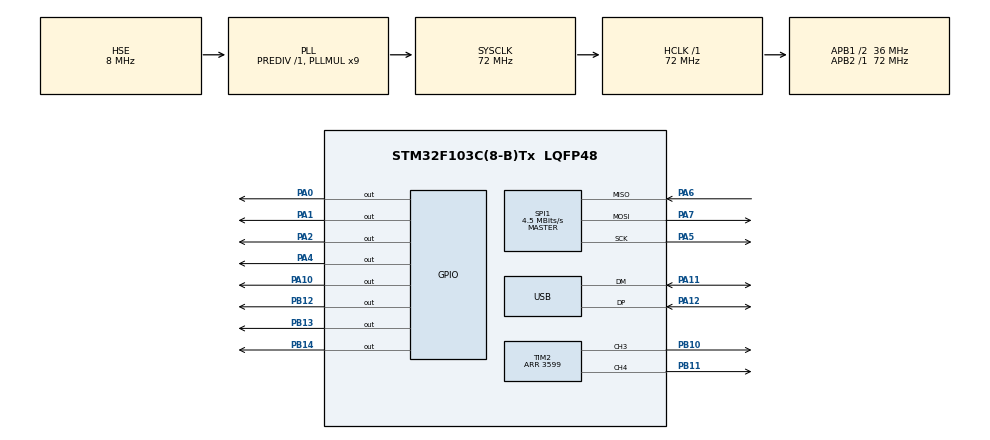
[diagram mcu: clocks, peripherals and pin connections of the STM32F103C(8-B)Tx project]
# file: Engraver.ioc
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Mcu.Family=STM32F1
Mcu.Name=STM32F103C(8-B)Tx
Mcu.Package=LQFP48
NVIC.PriorityGroup=NVIC_PRIORITYGROUP_4
NVIC.TIM4_IRQn=true\:0\:0\:false\:false\:true
NVIC.USB_LP_CAN1_RX0_IRQn=true\:0\:0\:false\:false\:true
PA0-WKUP.GPIO_Speed=GPIO_SPEED_FREQ_HIGH
PA0-WKUP.Signal=GPIO_Output
PA1.GPIO_Speed=GPIO_SPEED_FREQ_HIGH
PA1.Signal=GPIO_Output
PA10.GPIO_Speed=GPIO_SPEED_FREQ_HIGH
PA10.PinState=GPIO_PIN_SET
PA10.Signal=GPIO_Output
PA11.Mode=Device
PA11.Signal=USB_DM
PA12.Mode=Device
PA12.Signal=USB_DP
PA13.Mode=Serial_Wire
PA13.Signal=SYS_JTMS-SWDIO
PA14.Mode=Serial_Wire
PA14.Signal=SYS_JTCK-SWCLK
PA2.GPIO_Speed=GPIO_SPEED_FREQ_HIGH
PA2.Signal=GPIO_Output
PA4.GPIO_Speed=GPIO_SPEED_FREQ_HIGH
PA4.Signal=GPIO_Output
PA5.Mode=Full_Duplex_Master
PA5.Signal=SPI1_SCK
PA6.Mode=Full_Duplex_Master
PA6.Signal=SPI1_MISO
PA7.Mode=Full_Duplex_Master
PA7.Signal=SPI1_MOSI
PB10.GPIO_Speed=GPIO_SPEED_FREQ_HIGH
PB10.Signal=S_TIM2_CH3
PB11.GPIO_Speed=GPIO_SPEED_FREQ_HIGH
PB11.Signal=S_TIM2_CH4
PB12.GPIO_Speed=GPIO_SPEED_FREQ_HIGH
PB12.Signal=GPIO_Output
PB13.GPIO_Speed=GPIO_SPEED_FREQ_HIGH
PB13.Signal=GPIO_Output
PB14.GPIO_Speed=GPIO_SPEED_FREQ_HIGH
PB14.Signal=GPIO_Output
PD0-OSC_IN.Mode=HSE-External-Oscillator
PD0-OSC_IN.Signal=RCC_OSC_IN
PD1-OSC_OUT.Mode=HSE-External-Oscillator
PD1-OSC_OUT.Signal=RCC_OSC_OUT
ProjectManager.HeapSize=0x200
ProjectManager.StackSize=0x400
ProjectManager.TargetToolchain=SW4STM32
RCC.AHBFreq_Value=72000000
RCC.APB1CLKDivider=RCC_HCLK_DIV2
RCC.APB1Freq_Value=36000000
RCC.APB1TimFreq_Value=72000000
RCC.APB2Freq_Value=72000000
RCC.APB2TimFreq_Value=72000000
RCC.HCLKFreq_Value=72000000
RCC.HSIState=RCC_HSI_ON
RCC.PLLMUL=RCC_PLL_MUL9
RCC.SYSCLKFreq_VALUE=72000000
RCC.SYSCLKSource=RCC_SYSCLKSOURCE_PLLCLK
RCC.USBFreq_Value=48000000
RCC.USBPrescaler=RCC_USBCLKSOURCE_PLL_DIV1_5
SH.S_TIM2_CH3.0=TIM2_CH3,PWM Generation3 CH3
SH.S_TIM2_CH4.0=TIM2_CH4,PWM Generation4 CH4
SPI1.BaudRatePrescaler=SPI_BAUDRATEPRESCALER_16
SPI1.CalculateBaudRate=4.5 MBits/s
SPI1.Mode=SPI_MODE_MASTER
TIM2.Channel-PWM\ Generation3\ CH3=TIM_CHANNEL_3
TIM2.Channel-PWM\ Generation4\ CH4=TIM_CHANNEL_4
TIM2.OCFastMode_PWM-PWM\ Generation3\ CH3=TIM_OCFAST_ENABLE
TIM2.OCFastMode_PWM-PWM\ Generation4\ CH4=TIM_OCFAST_ENABLE
TIM2.Period=3599
TIM3.Period=71
TIM4.Period=65535
TIM4.Prescaler=99
USB_DEVICE.CLASS_NAME_FS=CDC
USB_DEVICE.USBD_HandleTypeDef=hUsbDeviceFS
USB_DEVICE.VirtualMode=Cdc
USB_DEVICE.VirtualModeFS=Cdc_FS
VP_CRC_VS_CRC.Mode=CRC_Activate
VP_TIM3_VS_ClockSourceINT.Mode=Internal
VP_TIM4_VS_ClockSourceINT.Mode=Internal
VP_USB_DEVICE_VS_USB_DEVICE_CDC_FS.Mode=CDC_FS
board=Engraver

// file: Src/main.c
/**
  ******************************************************************************
  * File Name          : main.c
  * Description        : Main program body
  ******************************************************************************
  *
  * COPYRIGHT(c) 2016 STMicroelectronics
  *
  * Redistribution and use in source and binary forms, with or without modification,
  * are permitted provided that the following conditions are met:
  *   1. Redistributions of source code must retain the above copyright notice,
  *      this list of conditions and the following disclaimer.
  *   2. Redistributions in binary form must reproduce the above copyright notice,
  *      this list of conditions and the following disclaimer in the documentation
  *      and/or other materials provided with the distribution.
  *   3. Neither the name of STMicroelectronics nor the names of its contributors
  *      may be used to endorse or promote products derived from this software
  *      without specific prior written permission.
  *
  * THIS SOFTWARE IS PROVIDED BY THE COPYRIGHT HOLDERS AND CONTRIBUTORS "AS IS"
  * AND ANY EXPRESS OR IMPLIED WARRANTIES, INCLUDING, BUT NOT LIMITED TO, THE
  * IMPLIED WARRANTIES OF MERCHANTABILITY AND FITNESS FOR A PARTICULAR PURPOSE ARE
  * DISCLAIMED. IN NO EVENT SHALL THE COPYRIGHT HOLDER OR CONTRIBUTORS BE LIABLE
  * FOR ANY DIRECT, INDIRECT, INCIDENTAL, SPECIAL, EXEMPLARY, OR CONSEQUENTIAL
  * DAMAGES (INCLUDING, BUT NOT LIMITED TO, PROCUREMENT OF SUBSTITUTE GOODS OR
  * SERVICES; LOSS OF USE, DATA, OR PROFITS; OR BUSINESS INTERRUPTION) HOWEVER
  * CAUSED AND ON ANY THEORY OF LIABILITY, WHETHER IN CONTRACT, STRICT LIABILITY,
  * OR TORT (INCLUDING NEGLIGENCE OR OTHERWISE) ARISING IN ANY WAY OUT OF THE USE
  * OF THIS SOFTWARE, EVEN IF ADVISED OF THE POSSIBILITY OF SUCH DAMAGE.
  *
  ******************************************************************************
  */
#include "stm32f1xx_hal.h"
#include "crc.h"
#include "spi.h"
#include "tim.h"
#include "usb_device.h"
#include "gpio.h"

/* USER CODE BEGIN PV */
/* Private variables ---------------------------------------------------------*/

/* USER CODE END PV */

void SystemClock_Config(void);

/* USER CODE BEGIN PFP */
/* Private function prototypes -----------------------------------------------*/

/* USER CODE END PFP */

/* USER CODE BEGIN 0 */
extern void Init();
extern void Loop();
/* USER CODE END 0 */

int main(void)
{

  /* MCU Configuration----------------------------------------------------------*/

  /* Reset of all peripherals, Initializes the Flash interface and the Systick. */
  HAL_Init();

  /* Configure the system clock */
  SystemClock_Config();

  /* Initialize all configured peripherals */
  MX_GPIO_Init();
  MX_TIM2_Init();
  MX_USB_DEVICE_Init();
  MX_CRC_Init();
  MX_SPI1_Init();
  MX_TIM3_Init();
  MX_TIM4_Init();

  /* USER CODE BEGIN 2 */
  Init();
  /* USER CODE END 2 */

  /* Infinite loop */
  while (1)
  {

  /* USER CODE BEGIN 3 */
	  Loop();
  }
  /* USER CODE END 3 */

}

/** System Clock Configuration
*/
void SystemClock_Config(void)
{

  RCC_OscInitTypeDef RCC_OscInitStruct;
  RCC_ClkInitTypeDef RCC_ClkInitStruct;
  RCC_PeriphCLKInitTypeDef PeriphClkInit;

  RCC_OscInitStruct.OscillatorType = RCC_OSCILLATORTYPE_HSE;
  RCC_OscInitStruct.HSEState = RCC_HSE_ON;
  RCC_OscInitStruct.HSEPredivValue = RCC_HSE_PREDIV_DIV1;
  RCC_OscInitStruct.PLL.PLLState = RCC_PLL_ON;
  RCC_OscInitStruct.PLL.PLLSource = RCC_PLLSOURCE_HSE;
  RCC_OscInitStruct.PLL.PLLMUL = RCC_PLL_MUL9;
  HAL_RCC_OscConfig(&RCC_OscInitStruct);

  RCC_ClkInitStruct.ClockType = RCC_CLOCKTYPE_HCLK|RCC_CLOCKTYPE_SYSCLK
                              |RCC_CLOCKTYPE_PCLK1|RCC_CLOCKTYPE_PCLK2;
  RCC_ClkInitStruct.SYSCLKSource = RCC_SYSCLKSOURCE_PLLCLK;
  RCC_ClkInitStruct.AHBCLKDivider = RCC_SYSCLK_DIV1;
  RCC_ClkInitStruct.APB1CLKDivider = RCC_HCLK_DIV2;
  RCC_ClkInitStruct.APB2CLKDivider = RCC_HCLK_DIV1;
  HAL_RCC_ClockConfig(&RCC_ClkInitStruct, FLASH_LATENCY_2);

  PeriphClkInit.PeriphClockSelection = RCC_PERIPHCLK_USB;
  PeriphClkInit.UsbClockSelection = RCC_USBCLKSOURCE_PLL_DIV1_5;
  HAL_RCCEx_PeriphCLKConfig(&PeriphClkInit);

  HAL_SYSTICK_Config(HAL_RCC_GetHCLKFreq()/1000);

  HAL_SYSTICK_CLKSourceConfig(SYSTICK_CLKSOURCE_HCLK);

  /* SysTick_IRQn interrupt configuration */
  HAL_NVIC_SetPriority(SysTick_IRQn, 0, 0);
}

/************************ (C) COPYRIGHT STMicroelectronics *****END OF FILE****/
